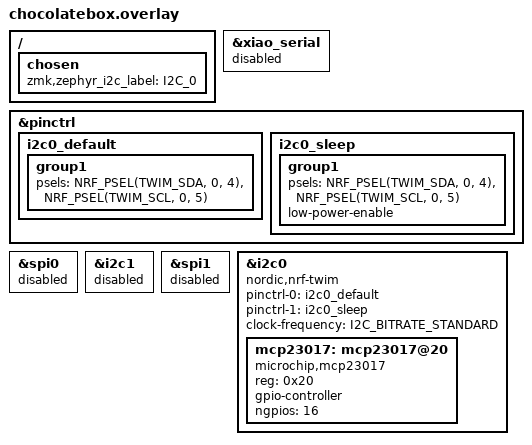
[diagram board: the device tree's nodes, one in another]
/*
 * chocolatebox.overlay - Verification Overlay for I2C0/MCP23017
 *
 * 目的: I2C0 と MCP23017 の認識だけに絞って問題を確認するための
 * 一時的な検証用ファイルです。
 * 他の機能 (SPIトラックボール、キーマトリックス等) は無効化しています。
 */

// kscan や matrix_transform に関連しないヘッダーのみ残す
// #include <dt-bindings/zmk/matrix_transform.h> // kscan無効化のため不要
// #include "./chocolatebox-layouts.dtsi" // kscan無効化のため不要
#include <zephyr/dt-bindings/input/input-event-codes.h> // GPIOフラグ等で使われる可能性があるので残す

// --- マクロ定義は不要になりました ---
// #define MATRIX_TRANSFORM_NO_OP 0xFFFF
// #define RC(r, c) (((r) & 0xFF) | (((c) & 0xFF) << 8))

/ { // ルートノード
    // chosen ノードから kscan, matrix_transform, pointing_device などを一時的に削除
    chosen {
         // I2C0 をデバッグしやすくするために明示的に指定 (必須ではない)
        zmk,zephyr_i2c_label = "I2C_0";
    };

    // --- default_transform, kscan0, sensors などを一時的にコメントアウト ---
    /*
    model = "chocolatebox";
    compatible = "chocolatebox";
    default_transform: keymap_transform_0 { ... };
    kscan0: kscan0 { ... };
    trackball_listener { ... }; // sensors ノードも無効化
    */
};

/* シリアルポートの無効化 */
&xiao_serial {
    status = "disabled";
};

/* ピン制御設定 */
&pinctrl {
    // --- SPI1 ピン設定は一時的にコメントアウト ---
    /*
    spi1_default: spi1_default { ... };
    spi1_sleep: spi1_sleep { ... };
    */

    // +++ I2C0 ピン設定 (P0.04=SDA0, P0.05=SCL0) を定義 +++
    // MCP23017 をこれらのピンに接続していることを確認
    i2c0_default: i2c0_default {
        group1 {
            psels = <NRF_PSEL(TWIM_SDA, 0, 4)>, // P0.04 (XIAO D4)
                    <NRF_PSEL(TWIM_SCL, 0, 5)>; // P0.05 (XIAO D5)
            // 外部プルアップ抵抗を付けたので、内部プルアップは削除
        };
    };
    i2c0_sleep: i2c0_sleep {
        group1 {
            psels = <NRF_PSEL(TWIM_SDA, 0, 4)>,
                    <NRF_PSEL(TWIM_SCL, 0, 5)>;
            low-power-enable;
        };
    };
};

/* SPI0 は無効化 */
&spi0 {
    status = "disabled";
};

/* I2C1 は無効化 */
&i2c1 {
    status = "disabled";
};

/* SPI1 は無効化 (トラックボールも一時的に無効化) */
&spi1 {
    status = "disabled";
};


/* I2C0 を有効化 (MCP23017 用) */
&i2c0 {
    status = "okay"; // ★ I2C インスタンス 0 を使用
    compatible = "nordic,nrf-twim";
    pinctrl-0 = <&i2c0_default>; // ★ i2c0 用の pinctrl を参照
    pinctrl-1 = <&i2c0_sleep>;
    pinctrl-names = "default", "sleep";
    clock-frequency = <I2C_BITRATE_STANDARD>;

    // ★ MCP23017 の定義
    mcp23017: mcp23017@20 {
        // compatible = "microchip,mcp230xx"; // 元の設定
        compatible = "microchip,mcp23017"; // ★ より具体的な compatible 文字列を試す
        reg = <0x20>; // I2Cアドレス
        status = "okay";
        gpio-controller;
        #gpio-cells = <2>;
        ngpios = <16>;
    };
};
